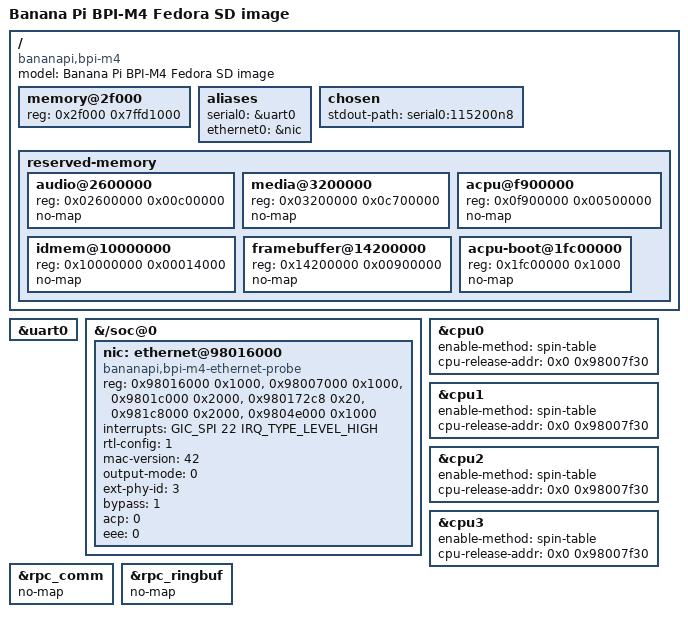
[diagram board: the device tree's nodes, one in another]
// SPDX-License-Identifier: (GPL-2.0-or-later OR BSD-2-Clause)
/dts-v1/;
#include "rtd1395.dtsi"
/ {
    compatible = "bananapi,bpi-m4", "realtek,rtd1395";
    model = "Banana Pi BPI-M4 Fedora SD image";
    memory@2f000 { device_type = "memory"; reg = <0x2f000 0x7ffd1000>; };
    aliases { serial0 = &uart0; ethernet0 = &nic; };
    chosen { stdout-path = "serial0:115200n8"; };
};
&uart0 { status = "okay"; };
&{/soc@0} {
    nic: ethernet@98016000 {
        compatible = "bananapi,bpi-m4-ethernet-probe";
        reg = <0x98016000 0x1000>, <0x98007000 0x1000>,
              <0x9801c000 0x2000>, <0x980172c8 0x20>,
              <0x981c8000 0x2000>, <0x9804e000 0x1000>;
        interrupts = <GIC_SPI 22 IRQ_TYPE_LEVEL_HIGH>;
        rtl-config = <1>;
        mac-version = <42>;
        output-mode = <0>;
        ext-phy-id = <3>;
        bypass = <1>;
        acp = <0>;
        eee = <0>;
        status = "okay";
    };
};

&cpu0 { enable-method = "spin-table"; cpu-release-addr = <0x0 0x98007f30>; };
&cpu1 { enable-method = "spin-table"; cpu-release-addr = <0x0 0x98007f30>; };
&cpu2 { enable-method = "spin-table"; cpu-release-addr = <0x0 0x98007f30>; };
&cpu3 { enable-method = "spin-table"; cpu-release-addr = <0x0 0x98007f30>; };
&rpc_comm { no-map; };
&rpc_ringbuf { no-map; };
/ {
    reserved-memory {
        audio@2600000 { reg = <0x02600000 0x00c00000>; no-map; };
        media@3200000 { reg = <0x03200000 0x0c700000>; no-map; };
        acpu@f900000 { reg = <0x0f900000 0x00500000>; no-map; };
        idmem@10000000 { reg = <0x10000000 0x00014000>; no-map; };
        framebuffer@14200000 { reg = <0x14200000 0x00900000>; no-map; };
        acpu-boot@1fc00000 { reg = <0x1fc00000 0x1000>; no-map; };
    };
};
